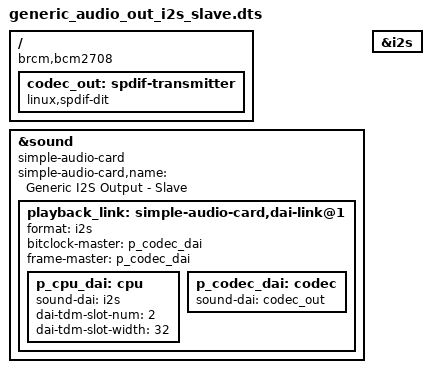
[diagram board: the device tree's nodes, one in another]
// Device Tree Overlay for generic I2S audio output
// 32 bit, 2 channels, bclk = 64 x fs
// Raspberry Pi is the clock slave --> clocks are inputs

/dts-v1/;
/plugin/;

/ {
    compatible = "brcm,bcm2708", "brcm,bcm2710", "brcm,bcm2711";

    fragment@0 {
        target = <&sound>;
        __overlay__ {

            compatible = "simple-audio-card";
            simple-audio-card,name = "Generic I2S Output - Slave";
			
            status="okay";

            playback_link: simple-audio-card,dai-link@1 {
                format = "i2s";
				
		bitclock-master = <&p_codec_dai>;
                frame-master = <&p_codec_dai>;

                p_cpu_dai: cpu {
                    sound-dai = <&i2s>;

		    //TDM slot configuration - BCLK ratio: 64 x Fs
                    dai-tdm-slot-num = <2>;
                    dai-tdm-slot-width = <32>;
                
				};

                p_codec_dai: codec {
                    sound-dai = <&codec_out>;
                };
            };
        };
    };

    fragment@1 {
        target-path = "/";
        __overlay__ {
            codec_out: spdif-transmitter {
                #address-cells = <0>;
                #size-cells = <0>;
                #sound-dai-cells = <0>;
                compatible = "linux,spdif-dit";
                status = "okay";
            };
        };
    };

    fragment@2 {
        target = <&i2s>;
        __overlay__ {
            #sound-dai-cells = <0>;
            status = "okay";
        };
    };
};
